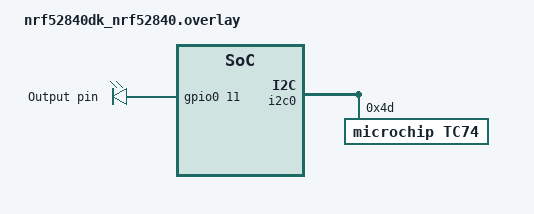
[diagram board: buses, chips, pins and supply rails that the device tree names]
&i2c0 {
    status = "okay";

    tc74sensor: tc74@4d {
        compatible = "microchip,tc74";
        reg = <0x4d>;
        label = "TC74";
    };
};
 
/ {
    leds {
        compatible = "gpio-leds";

        output_pin: my_output_pin {
            gpios = <&gpio0 11 GPIO_ACTIVE_HIGH>;
            label = "Output pin";
        };
    };

    aliases {
        outputpin = &output_pin; 
    };
};

